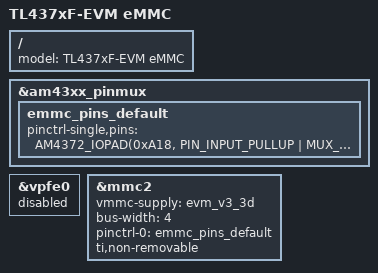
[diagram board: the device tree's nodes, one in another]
/*
 * Copyright (C) 2015 GuangZhou Tronlong co., LTD - http://www.tronlong.com
 *
 * This program is free software; you can redistribute it and/or modify
 * it under the terms of the GNU General Public License version 2 as
 * published by the Free Software Foundation.
 */

#include "tl437xf-evm.dts"

/ {
	model = "TL437xF-EVM eMMC";
};

&am43xx_pinmux {
	emmc_pins_default: emmc_pins_default {
		pinctrl-single,pins = <
			AM4372_IOPAD(0xA18, PIN_INPUT_PULLUP | MUX_MODE1) /* cam0_data4.mmc1_dat0 */
			AM4372_IOPAD(0xA1c, PIN_INPUT_PULLUP | MUX_MODE1) /* cam0_data5.mmc1_dat1 */
			AM4372_IOPAD(0xA20, PIN_INPUT_PULLUP | MUX_MODE1) /* cam0_data6.mmc1_dat2 */
			AM4372_IOPAD(0xA24, PIN_INPUT_PULLUP | MUX_MODE1) /* cam0_data7.mmc1_dat3 */
			AM4372_IOPAD(0xA10, PIN_INPUT_PULLUP | MUX_MODE1) /* cam0_data2.mmc1_clk */
			AM4372_IOPAD(0xA14, PIN_INPUT_PULLUP | MUX_MODE1) /* cam0_data3.mmc1_cmd */
		>;
	};
};

&vpfe0 {
	status = "disbale"; /* Disable vpfe0 when enabling mmc2 */
};

/* eMMC sits on mmc2 */
&mmc2 {
	status = "okay";
	vmmc-supply = <&evm_v3_3d>;
	bus-width = <4>;
	pinctrl-names = "default";
	pinctrl-0 = <&emmc_pins_default>;
	ti,non-removable;
};
